# ADuCM363 register map
Vendor: Analog Devices Inc.; Series: ADuCM36x; File version: 0.1
CPU: CM3 r2p1, little endian, no MPU, no FPU, 3 interrupt priority bits
Registers are 16-bit, read-write, no defined reset value unless marked. A register's access mark holds for its fields unless they carry their own. Offsets are from the block's base; [hi:lo] are bit positions; {n}, {i} and the like mark numbered series.

## ADI_SPI0 — Serial Peripheral Interface
Base 0x40004000
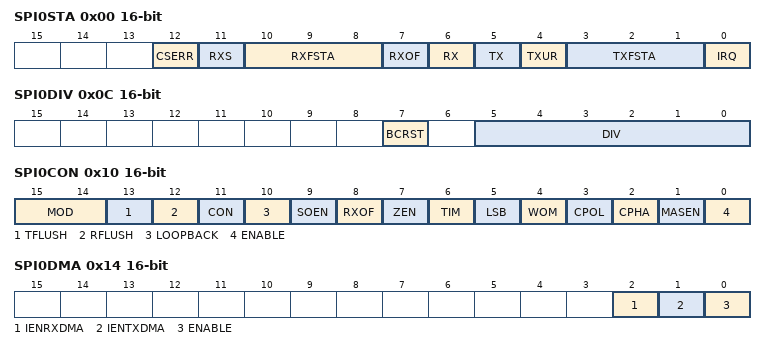
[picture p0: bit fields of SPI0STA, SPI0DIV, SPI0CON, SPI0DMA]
0x00 SPI0STA ro — Status Register
  [12] CSERR — Detected an abrupt CS deassertion
    0=CLR; 1=SET
  [11] RXS — Set when there are more bytes in the RX FIFO than the TIM bit says
    0=CLR; 1=SET
  [10:8] RXFSTA — Receive FIFO Status
    0=EMPTY; 1=ONEBYTE; 2=TWOBYTES; 3=THREEBYTES; 4=FOURBYTES
  [7] RXOF — Receive FIFO overflow
    0=CLR; 1=SET
  [6] RX — Set when a receive interrupt occurs
    0=CLR; 1=SET
  [5] TX — Set when a transmit interrupt occurs
    0=CLR; 1=SET
  [4] TXUR — Transmit FIFO underflow
    0=CLR; 1=SET
  [3:1] TXFSTA — transmit FIFO Status
    0=EMPTY; 1=ONEBYTE; 2=TWOBYTES; 3=THREEBYTES; 4=FOURBYTES
  [0] IRQ — Interrupt status bit
    0=CLR; 1=SET
0x04 SPI0RX 8-bit ro — 8-bit Receive register.
  [7:0] VALUE range 0x00000000..0x000000FF — Received data
0x08 SPI0TX 8-bit wo — 8-bit Transmit register
  [7:0] VALUE range 0x00000000..0x000000FF — Data to transmit
0x0C SPI0DIV — SPI Clock Divider Registers
  [7] BCRST — Bit counter reset
    0=DIS; 1=EN
  [5:0] DIV range 0x00000000..0x0000003F — Factor used to divide UCLK to generate the serial clock
0x10 SPI0CON — 16-bit configuration register
  [15:14] MOD — SPI IRQ Mode bits
    {v}=TX{v+1}RX{v+1} (v=0..3)
  [13] TFLUSH — TX FIFO Flush Enable bit
    0=DIS; 1=EN
  [12] RFLUSH — RX FIFO Flush Enable bit
    0=DIS; 1=EN
  [11] CON — Continuous transfer enable
    0=DIS; 1=EN
  [10] LOOPBACK — Loopback enable bit
    0=DIS; 1=EN
  [9] SOEN — Slave MISO output enable bit
    0=DIS; 1=EN
  [8] RXOF — RX Oveflow Overwrite enable
    0=DIS; 1=EN
  [7] ZEN — Transmit zeros when empty
    0=DIS; 1=EN
  [6] TIM — Transfer and interrupt mode
    0=RXRD (- Cleared by user to initiate transfer with a read of the SPIRX register); 1=TXWR (- Set by user to initiate transfer with a write to the SPITX register.)
  [5] LSB — LSB First Transfer enable
    0=DIS; 1=EN
  [4] WOM — Wired OR enable
    0=DIS; 1=EN
  [3] CPOL — Clock polarity mode
    0=LOW; 1=HIGH
  [2] CPHA — Clock phase mode
    0=SAMPLELEADING; 1=SAMPLETRAILING
  [1] MASEN — Master enable
    0=DIS; 1=EN
  [0] ENABLE — SPI Enable bit
    0=DIS; 1=EN
0x14 SPI0DMA — DMA enable register
  [all] fields
    0=DIS; 1=EN
  [2] IENRXDMA — Enable receive DMA request
  [1] IENTXDMA — Enable transmit DMA request
  [0] ENABLE — Enable DMA for data transfer
0x18 SPI0CNT ro — 8-bit received byte count register
  [7:0] VALUE range 0x00000000..0x000000FF — Count

## ADI_SPI1 — Serial Peripheral Interface
Base 0x40004400
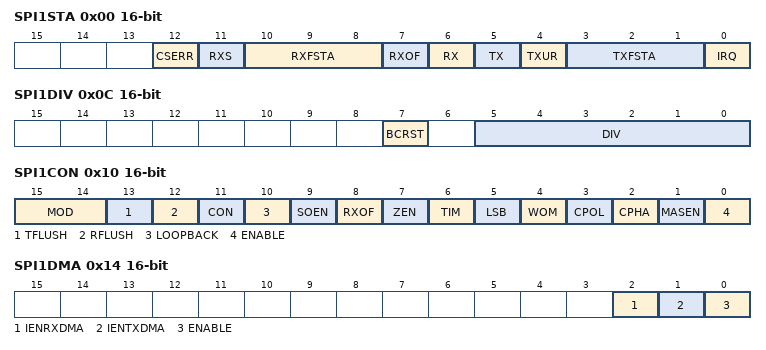
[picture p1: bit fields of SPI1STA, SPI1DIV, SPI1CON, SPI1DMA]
0x00 SPI1STA ro — Status Register
  [12] CSERR — Detected an abrupt CS deassertion
    0=CLR; 1=SET
  [11] RXS — Set when there are more bytes in the RX FIFO than the TIM bit says
    0=CLR; 1=SET
  [10:8] RXFSTA — Receive FIFO Status
    0=EMPTY; 1=ONEBYTE; 2=TWOBYTES; 3=THREEBYTES; 4=FOURBYTES
  [7] RXOF — Receive FIFO overflow
    0=CLR; 1=SET
  [6] RX — Set when a receive interrupt occurs
    0=CLR; 1=SET
  [5] TX — Set when a transmit interrupt occurs
    0=CLR; 1=SET
  [4] TXUR — Transmit FIFO underflow
    0=CLR; 1=SET
  [3:1] TXFSTA — transmit FIFO Status
    0=EMPTY; 1=ONEBYTE; 2=TWOBYTES; 3=THREEBYTES; 4=FOURBYTES
  [0] IRQ — Interrupt status bit
    0=CLR; 1=SET
0x04 SPI1RX 8-bit ro — 8-bit Receive register.
  [7:0] VALUE range 0x00000000..0x000000FF — Received data
0x08 SPI1TX 8-bit wo — 8-bit Transmit register
  [7:0] VALUE range 0x00000000..0x000000FF — Data to transmit
0x0C SPI1DIV — SPI Clock Divider Registers
  [7] BCRST — Bit counter reset
    0=DIS; 1=EN
  [5:0] DIV range 0x00000000..0x0000003F — Factor used to divide UCLK to generate the serial clock
0x10 SPI1CON — 16-bit configuration register
  [15:14] MOD — SPI IRQ Mode bits
    {v}=TX{v+1}RX{v+1} (v=0..3)
  [13] TFLUSH — TX FIFO Flush Enable bit
    0=DIS; 1=EN
  [12] RFLUSH — RX FIFO Flush Enable bit
    0=DIS; 1=EN
  [11] CON — Continuous transfer enable
    0=DIS; 1=EN
  [10] LOOPBACK — Loopback enable bit
    0=DIS; 1=EN
  [9] SOEN — Slave MISO output enable bit
    0=DIS; 1=EN
  [8] RXOF — RX Oveflow Overwrite enable
    0=DIS; 1=EN
  [7] ZEN — Transmit zeros when empty
    0=DIS; 1=EN
  [6] TIM — Transfer and interrupt mode
    0=RXRD (- Cleared by user to initiate transfer with a read of the SPIRX register); 1=TXWR (- Set by user to initiate transfer with a write to the SPITX register.)
  [5] LSB — LSB First Transfer enable
    0=DIS; 1=EN
  [4] WOM — Wired OR enable
    0=DIS; 1=EN
  [3] CPOL — Clock polarity mode
    0=LOW; 1=HIGH
  [2] CPHA — Clock phase mode
    0=SAMPLELEADING; 1=SAMPLETRAILING
  [1] MASEN — Master enable
    0=DIS; 1=EN
  [0] ENABLE — SPI Enable bit
    0=DIS; 1=EN
0x14 SPI1DMA — DMA enable register
  [all] fields
    0=DIS; 1=EN
  [2] IENRXDMA — Enable receive DMA request
  [1] IENTXDMA — Enable transmit DMA request
  [0] ENABLE — Enable DMA for data transfer
0x18 SPI1CNT ro — 8-bit received byte count register
  [7:0] VALUE range 0x00000000..0x000000FF — Count
